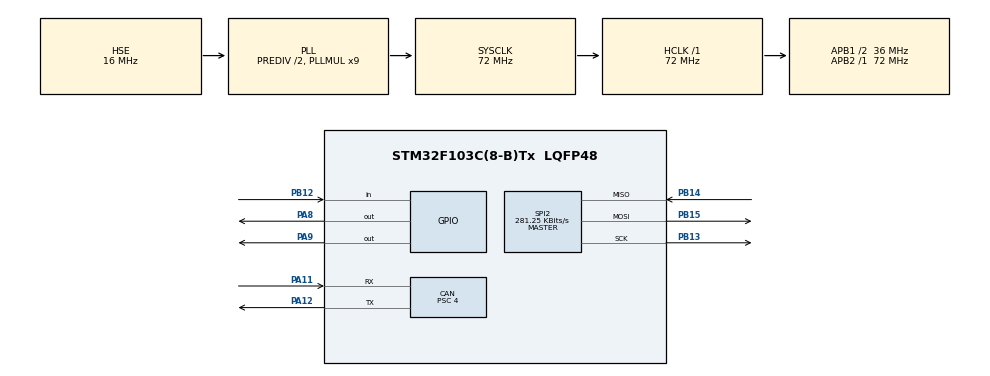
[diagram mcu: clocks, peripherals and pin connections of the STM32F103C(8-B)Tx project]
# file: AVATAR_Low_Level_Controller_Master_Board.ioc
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CAN.BS1=CAN_BS1_15TQ
CAN.BS2=CAN_BS2_2TQ
CAN.CalculateBaudRate=500000
CAN.CalculateTimeBit=2000
CAN.CalculateTimeQuantum=111.11111111111111
CAN.Prescaler=4
Dma.Request0=SPI2_RX
Dma.Request1=SPI2_TX
Dma.SPI2_RX.0.Direction=DMA_PERIPH_TO_MEMORY
Dma.SPI2_RX.0.Instance=DMA1_Channel4
Dma.SPI2_RX.0.MemDataAlignment=DMA_MDATAALIGN_BYTE
Dma.SPI2_RX.0.MemInc=DMA_MINC_ENABLE
Dma.SPI2_RX.0.Mode=DMA_NORMAL
Dma.SPI2_RX.0.PeriphDataAlignment=DMA_PDATAALIGN_BYTE
Dma.SPI2_RX.0.PeriphInc=DMA_PINC_DISABLE
Dma.SPI2_RX.0.Priority=DMA_PRIORITY_LOW
Dma.SPI2_TX.1.Direction=DMA_MEMORY_TO_PERIPH
Dma.SPI2_TX.1.Instance=DMA1_Channel5
Dma.SPI2_TX.1.MemDataAlignment=DMA_MDATAALIGN_BYTE
Dma.SPI2_TX.1.MemInc=DMA_MINC_ENABLE
Dma.SPI2_TX.1.Mode=DMA_NORMAL
Dma.SPI2_TX.1.PeriphDataAlignment=DMA_PDATAALIGN_BYTE
Dma.SPI2_TX.1.PeriphInc=DMA_PINC_DISABLE
Dma.SPI2_TX.1.Priority=DMA_PRIORITY_LOW
FREERTOS.Tasks01=spiTask,-3,128,SPITaskCallback,Default,NULL,Dynamic,NULL,NULL;canRxTask,-3,128,CANRXTaskFunction,Default,NULL,Dynamic,NULL,NULL;canTxTask,-3,128,CanTXTaskFunction,Default,NULL,Dynamic,NULL,NULL
FREERTOS.configUSE_NEWLIB_REENTRANT=1
Mcu.Family=STM32F1
Mcu.Name=STM32F103C(8-B)Tx
Mcu.Package=LQFP48
NVIC.DMA1_Channel4_IRQn=true\:5\:0\:true\:false\:true\:true\:false\:true\:true
NVIC.DMA1_Channel5_IRQn=true\:5\:0\:true\:false\:true\:true\:false\:true\:true
NVIC.PriorityGroup=NVIC_PRIORITYGROUP_4
NVIC.TIM1_BRK_IRQn=true\:5\:0\:false\:false\:true\:true\:true\:true\:true
NVIC.TIM1_CC_IRQn=true\:5\:0\:false\:false\:true\:true\:true\:true\:true
NVIC.TIM1_TRG_COM_IRQn=true\:5\:0\:false\:false\:true\:true\:true\:true\:true
NVIC.TIM1_UP_IRQn=true\:5\:0\:false\:false\:true\:true\:true\:true\:true
NVIC.TIM4_IRQn=true\:15\:0\:false\:false\:true\:false\:false\:true\:true
NVIC.TimeBase=TIM4_IRQn
NVIC.TimeBaseIP=TIM4
NVIC.USB_LP_CAN1_RX0_IRQn=true\:5\:0\:true\:false\:true\:true\:true\:true\:true
PA11.Mode=CAN_Activate
PA11.Signal=CAN_RX
PA12.Mode=CAN_Activate
PA12.Signal=CAN_TX
PA13.Mode=Serial_Wire
PA13.Signal=SYS_JTMS-SWDIO
PA14.Mode=Serial_Wire
PA14.Signal=SYS_JTCK-SWCLK
PA8.Signal=GPIO_Output
PA9.Signal=GPIO_Output
PB12.Signal=GPIO_Input
PB13.Mode=Full_Duplex_Master
PB13.Signal=SPI2_SCK
PB14.Mode=Full_Duplex_Master
PB14.Signal=SPI2_MISO
PB15.Mode=Full_Duplex_Master
PB15.Signal=SPI2_MOSI
PD0-OSC_IN.Mode=HSE-External-Oscillator
PD0-OSC_IN.Signal=RCC_OSC_IN
PD1-OSC_OUT.Mode=HSE-External-Oscillator
PD1-OSC_OUT.Signal=RCC_OSC_OUT
ProjectManager.HeapSize=0x200
ProjectManager.StackSize=0x400
ProjectManager.TargetToolchain=STM32CubeIDE
RCC.AHBFreq_Value=72000000
RCC.APB1CLKDivider=RCC_HCLK_DIV2
RCC.APB1Freq_Value=36000000
RCC.APB1TimFreq_Value=72000000
RCC.APB2Freq_Value=72000000
RCC.APB2TimFreq_Value=72000000
RCC.HCLKFreq_Value=72000000
RCC.HSEDivPLL=RCC_HSE_PREDIV_DIV2
RCC.HSE_VALUE=16000000
RCC.PLLMUL=RCC_PLL_MUL9
RCC.PLLSourceVirtual=RCC_PLLSOURCE_HSE
RCC.SYSCLKFreq_VALUE=72000000
RCC.SYSCLKSource=RCC_SYSCLKSOURCE_PLLCLK
RCC.USBFreq_Value=72000000
SPI2.BaudRatePrescaler=SPI_BAUDRATEPRESCALER_128
SPI2.CLKPhase=SPI_PHASE_2EDGE
SPI2.CLKPolarity=SPI_POLARITY_LOW
SPI2.CalculateBaudRate=281.25 KBits/s
SPI2.Direction=SPI_DIRECTION_2LINES
SPI2.Mode=SPI_MODE_MASTER
SPI2.VirtualType=VM_MASTER
TIM1.Period=10-1
TIM1.Prescaler=7200-1
VP_FREERTOS_VS_CMSIS_V1.Mode=CMSIS_V1
VP_SYS_VS_tim4.Mode=TIM4
VP_TIM1_VS_ClockSourceINT.Mode=Internal
board=custom

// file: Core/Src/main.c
/* USER CODE BEGIN Header */
/**
  ******************************************************************************
  * @file           : main.c
  * @brief          : Main program body
  ******************************************************************************
  * @attention
  *
  * Copyright (c) 2024 STMicroelectronics.
  * All rights reserved.
  *
  * This software is licensed under terms that can be found in the LICENSE file
  * in the root directory of this software component.
  * If no LICENSE file comes with this software, it is provided AS-IS.
  *
  ******************************************************************************
  */
/* USER CODE END Header */
#include "main.h"
#include "cmsis_os.h"

/* USER CODE BEGIN Includes */
#include "low_level_controller_master_main.h"
#include "low_level_controller_master_callbacks.h"
/* USER CODE END Includes */

CAN_HandleTypeDef hcan;

SPI_HandleTypeDef hspi2;
DMA_HandleTypeDef hdma_spi2_rx;
DMA_HandleTypeDef hdma_spi2_tx;

TIM_HandleTypeDef htim1;

osThreadId spiTaskHandle;
osThreadId canRxTaskHandle;
osThreadId canTxTaskHandle;

void SystemClock_Config(void);
static void MX_GPIO_Init(void);
static void MX_DMA_Init(void);
static void MX_CAN_Init(void);
static void MX_SPI2_Init(void);
static void MX_TIM1_Init(void);
void SPITaskCallback(void const * argument);
void CANRXTaskFunction(void const * argument);
void CanTXTaskFunction(void const * argument);

int main(void)
{

  /* MCU Configuration--------------------------------------------------------*/

  /* Reset of all peripherals, Initializes the Flash interface and the Systick. */
  HAL_Init();

  /* Configure the system clock */
  SystemClock_Config();

  /* Initialize all configured peripherals */
  MX_GPIO_Init();
  MX_DMA_Init();
  MX_CAN_Init();
  MX_SPI2_Init();
  MX_TIM1_Init();
  /* USER CODE BEGIN 2 */

  Start();

  /* USER CODE END 2 */

  /* Create the thread(s) */
  /* definition and creation of spiTask */
  osThreadDef(spiTask, SPITaskCallback, osPriorityIdle, 0, 128);
  spiTaskHandle = osThreadCreate(osThread(spiTask), NULL);

  /* definition and creation of canRxTask */
  osThreadDef(canRxTask, CANRXTaskFunction, osPriorityIdle, 0, 128);
  canRxTaskHandle = osThreadCreate(osThread(canRxTask), NULL);

  /* definition and creation of canTxTask */
  osThreadDef(canTxTask, CanTXTaskFunction, osPriorityIdle, 0, 128);
  canTxTaskHandle = osThreadCreate(osThread(canTxTask), NULL);

  /* Start scheduler */
  osKernelStart();

  /* We should never get here as control is now taken by the scheduler */

  /* Infinite loop */
  while (1)
  {

  }
}

void SystemClock_Config(void)
{
  RCC_OscInitTypeDef RCC_OscInitStruct = {0};
  RCC_ClkInitTypeDef RCC_ClkInitStruct = {0};

  /** Initializes the RCC Oscillators according to the specified parameters
  * in the RCC_OscInitTypeDef structure.
  */
  RCC_OscInitStruct.OscillatorType = RCC_OSCILLATORTYPE_HSE;
  RCC_OscInitStruct.HSEState = RCC_HSE_ON;
  RCC_OscInitStruct.HSEPredivValue = RCC_HSE_PREDIV_DIV2;
  RCC_OscInitStruct.HSIState = RCC_HSI_ON;
  RCC_OscInitStruct.PLL.PLLState = RCC_PLL_ON;
  RCC_OscInitStruct.PLL.PLLSource = RCC_PLLSOURCE_HSE;
  RCC_OscInitStruct.PLL.PLLMUL = RCC_PLL_MUL9;
  if (HAL_RCC_OscConfig(&RCC_OscInitStruct) != HAL_OK)
  {
    Error_Handler();
  }

  /** Initializes the CPU, AHB and APB buses clocks
  */
  RCC_ClkInitStruct.ClockType = RCC_CLOCKTYPE_HCLK|RCC_CLOCKTYPE_SYSCLK
                              |RCC_CLOCKTYPE_PCLK1|RCC_CLOCKTYPE_PCLK2;
  RCC_ClkInitStruct.SYSCLKSource = RCC_SYSCLKSOURCE_PLLCLK;
  RCC_ClkInitStruct.AHBCLKDivider = RCC_SYSCLK_DIV1;
  RCC_ClkInitStruct.APB1CLKDivider = RCC_HCLK_DIV2;
  RCC_ClkInitStruct.APB2CLKDivider = RCC_HCLK_DIV1;

  if (HAL_RCC_ClockConfig(&RCC_ClkInitStruct, FLASH_LATENCY_2) != HAL_OK)
  {
    Error_Handler();
  }
}

static void MX_CAN_Init(void)
{

  hcan.Instance = CAN1;
  hcan.Init.Prescaler = 4;
  hcan.Init.Mode = CAN_MODE_NORMAL;
  hcan.Init.SyncJumpWidth = CAN_SJW_1TQ;
  hcan.Init.TimeSeg1 = CAN_BS1_15TQ;
  hcan.Init.TimeSeg2 = CAN_BS2_2TQ;
  hcan.Init.TimeTriggeredMode = DISABLE;
  hcan.Init.AutoBusOff = DISABLE;
  hcan.Init.AutoWakeUp = DISABLE;
  hcan.Init.AutoRetransmission = DISABLE;
  hcan.Init.ReceiveFifoLocked = DISABLE;
  hcan.Init.TransmitFifoPriority = DISABLE;
  if (HAL_CAN_Init(&hcan) != HAL_OK)
  {
    Error_Handler();
  }

}

static void MX_SPI2_Init(void)
{

  /* SPI2 parameter configuration*/
  hspi2.Instance = SPI2;
  hspi2.Init.Mode = SPI_MODE_MASTER;
  hspi2.Init.Direction = SPI_DIRECTION_2LINES;
  hspi2.Init.DataSize = SPI_DATASIZE_8BIT;
  hspi2.Init.CLKPolarity = SPI_POLARITY_LOW;
  hspi2.Init.CLKPhase = SPI_PHASE_2EDGE;
  hspi2.Init.NSS = SPI_NSS_SOFT;
  hspi2.Init.BaudRatePrescaler = SPI_BAUDRATEPRESCALER_128;
  hspi2.Init.FirstBit = SPI_FIRSTBIT_MSB;
  hspi2.Init.TIMode = SPI_TIMODE_DISABLE;
  hspi2.Init.CRCCalculation = SPI_CRCCALCULATION_DISABLE;
  hspi2.Init.CRCPolynomial = 10;
  if (HAL_SPI_Init(&hspi2) != HAL_OK)
  {
    Error_Handler();
  }

}

static void MX_TIM1_Init(void)
{

  TIM_ClockConfigTypeDef sClockSourceConfig = {0};
  TIM_MasterConfigTypeDef sMasterConfig = {0};

  htim1.Instance = TIM1;
  htim1.Init.Prescaler = 7200-1;
  htim1.Init.CounterMode = TIM_COUNTERMODE_UP;
  htim1.Init.Period = 10-1;
  htim1.Init.ClockDivision = TIM_CLOCKDIVISION_DIV1;
  htim1.Init.RepetitionCounter = 0;
  htim1.Init.AutoReloadPreload = TIM_AUTORELOAD_PRELOAD_DISABLE;
  if (HAL_TIM_Base_Init(&htim1) != HAL_OK)
  {
    Error_Handler();
  }
  sClockSourceConfig.ClockSource = TIM_CLOCKSOURCE_INTERNAL;
  if (HAL_TIM_ConfigClockSource(&htim1, &sClockSourceConfig) != HAL_OK)
  {
    Error_Handler();
  }
  sMasterConfig.MasterOutputTrigger = TIM_TRGO_RESET;
  sMasterConfig.MasterSlaveMode = TIM_MASTERSLAVEMODE_DISABLE;
  if (HAL_TIMEx_MasterConfigSynchronization(&htim1, &sMasterConfig) != HAL_OK)
  {
    Error_Handler();
  }

}

static void MX_DMA_Init(void)
{

  /* DMA controller clock enable */
  __HAL_RCC_DMA1_CLK_ENABLE();

  /* DMA interrupt init */
  /* DMA1_Channel4_IRQn interrupt configuration */
  HAL_NVIC_SetPriority(DMA1_Channel4_IRQn, 5, 0);
  HAL_NVIC_EnableIRQ(DMA1_Channel4_IRQn);
  /* DMA1_Channel5_IRQn interrupt configuration */
  HAL_NVIC_SetPriority(DMA1_Channel5_IRQn, 5, 0);
  HAL_NVIC_EnableIRQ(DMA1_Channel5_IRQn);

}

static void MX_GPIO_Init(void)
{
  GPIO_InitTypeDef GPIO_InitStruct = {0};

  /* GPIO Ports Clock Enable */
  __HAL_RCC_GPIOD_CLK_ENABLE();
  __HAL_RCC_GPIOB_CLK_ENABLE();
  __HAL_RCC_GPIOA_CLK_ENABLE();

  /*Configure GPIO pin Output Level */
  HAL_GPIO_WritePin(GPIOA, GPIO_PIN_8|GPIO_PIN_9, GPIO_PIN_RESET);

  /*Configure GPIO pin : PB12 */
  GPIO_InitStruct.Pin = GPIO_PIN_12;
  GPIO_InitStruct.Mode = GPIO_MODE_INPUT;
  GPIO_InitStruct.Pull = GPIO_NOPULL;
  HAL_GPIO_Init(GPIOB, &GPIO_InitStruct);

  /*Configure GPIO pins : PA8 PA9 */
  GPIO_InitStruct.Pin = GPIO_PIN_8|GPIO_PIN_9;
  GPIO_InitStruct.Mode = GPIO_MODE_OUTPUT_PP;
  GPIO_InitStruct.Pull = GPIO_NOPULL;
  GPIO_InitStruct.Speed = GPIO_SPEED_FREQ_LOW;
  HAL_GPIO_Init(GPIOA, &GPIO_InitStruct);

}

void SPITaskCallback(void const * argument)
{
  /* USER CODE BEGIN 5 */
  /* Infinite loop */
  for(;;)
  {
	  SPI_Callback();
//	  osDelay(1);
  }
  /* USER CODE END 5 */
}

void CANRXTaskFunction(void const * argument)
{
  /* USER CODE BEGIN CANRXTaskFunction */
  /* Infinite loop */
  for(;;)
  {
	  CAN_RX_Callback();
//	  osDelay(1);
  }
  /* USER CODE END CANRXTaskFunction */
}

void CanTXTaskFunction(void const * argument)
{
  /* USER CODE BEGIN CanTXTaskFunction */
  /* Infinite loop */
  for(;;)
  {
	  Can_TX_Callback();
//	  osDelay(1);
  }
  /* USER CODE END CanTXTaskFunction */
}

void HAL_TIM_PeriodElapsedCallback(TIM_HandleTypeDef *htim)
{
  if (htim->Instance == TIM4) {
    HAL_IncTick();
  }
  /* USER CODE BEGIN Callback 1 */
  On_Timer_Tick(htim);
  /* USER CODE END Callback 1 */
}

void Error_Handler(void)
{
  __disable_irq();
  while (1)
  {
  }
}
